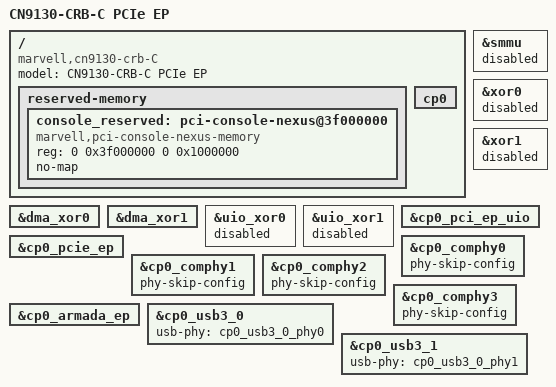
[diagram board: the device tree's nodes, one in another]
// SPDX-License-Identifier: GPL-2.0+
/*
 * Copyright (C) 2019 Marvell International Ltd.
 */

#include "cn9130-crb.dtsi"

/ {
	model = "CN9130-CRB-C PCIe EP";
	compatible = "marvell,cn9130-crb-C",
		"marvell,armada-ap807-quad",
		"marvell,armada-ap807";

	reserved-memory {
		#address-cells = <2>;
		#size-cells = <2>;
		ranges;

		/* The PCI console memory must be reserved */
		console_reserved: pci-console-nexus@3f000000 {
			compatible = "marvell,pci-console-nexus-memory";
			reg = <0 0x3f000000 0 0x1000000>;
			no-map;
		};
	};

	cp0 {
		/delete-node/ pcie@600000;
		/delete-node/ pcie@620000;
		/delete-node/ pcie@640000;
	};

};

&smmu {
	/* Should only be enabled on RC side */
	status = "disabled";
};

&dma_xor0 {
	status = "okay";
};

&dma_xor1 {
	status = "okay";
};

&xor0 {
	status = "disabled";
};

&xor1 {
	status = "disabled";
};

&uio_xor0 {
	status = "disabled";
};

&uio_xor1 {
	status = "disabled";
};

&cp0_pci_ep_uio {
	status = "okay";
};

&cp0_pcie_ep {
	status = "okay";
};

&cp0_comphy0 {
	phy-skip-config;
};

&cp0_comphy1 {
	phy-skip-config;
};

&cp0_comphy2 {
	phy-skip-config;
};

&cp0_comphy3 {
	phy-skip-config;
};

&cp0_armada_ep {
	status = "okay";
};

&cp0_usb3_0 {
	status = "okay";
	usb-phy = <&cp0_usb3_0_phy0>;
	phy-names = "usb";
};

&cp0_usb3_1 {
	status = "okay";
	usb-phy = <&cp0_usb3_0_phy1>;
	phy-names = "usb";
};
